VERSION ""

NS_ :

BS_:

BU_: XXX

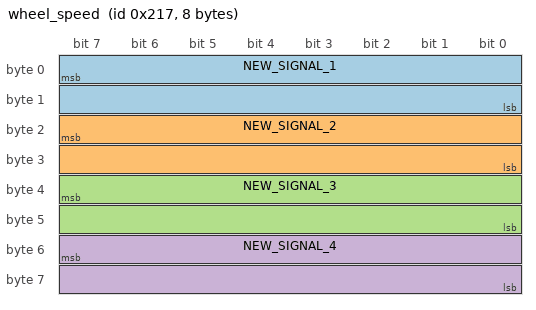
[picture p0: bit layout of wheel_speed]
BO_ 535 wheel_speed: 8 XXX
 SG_ NEW_SIGNAL_1 : 7|16@0+ (1,0) [0|65535] "" XXX
 SG_ NEW_SIGNAL_2 : 23|16@0+ (1,0) [0|65535] "" XXX
 SG_ NEW_SIGNAL_3 : 39|16@0+ (1,0) [0|65535] "" XXX
 SG_ NEW_SIGNAL_4 : 55|16@0+ (1,0) [0|65535] "" XXX

BO_ 133 steering_angle_2: 8 XXX
 SG_ NEW_SIGNAL_1 : 7|16@0+ (1,0) [0|65535] "" XXX
 SG_ NEW_SIGNAL_2 : 39|16@0+ (1,0) [0|65535] "" XXX

BO_ 516 engine_rpm: 8 XXX
 SG_ NEW_SIGNAL_1 : 15|16@0+ (1,0) [0|65535] "" XXX
 SG_ NEW_SIGNAL_2 : 31|16@0+ (1.3,0) [0|65535] "rpm" XXX
